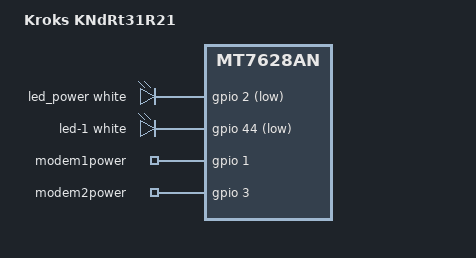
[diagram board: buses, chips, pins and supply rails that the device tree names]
#include "mt7628an_kroks_5eth.dtsi"

#include <dt-bindings/leds/common.h>

/ {
	compatible = "kroks,kndrt31r21", "mediatek,mt7628an-soc";
	model = "Kroks KNdRt31R21";

	aliases {
		led-boot = &led_power;
		led-failsafe = &led_power;
		led-running = &led_power;
		led-upgrade = &led_power;
	};

	gpio-leds {
		compatible = "gpio-leds";

		led_power: led-0 {
			color = <LED_COLOR_ID_WHITE>;
			gpios = <&gpio 2 GPIO_ACTIVE_LOW>;
			function = LED_FUNCTION_POWER;
		};

		led-1 {
			color = <LED_COLOR_ID_WHITE>;
			gpios = <&gpio 44 GPIO_ACTIVE_LOW>;
			function = LED_FUNCTION_WLAN;
			linux,default-trigger = "phy0tpt";
		};
	};

	gpio_export {
		compatible = "gpio-export";
		#size-cells = <0>;

		modem1power {
			gpio-export,name = "modem1power";
			gpio-export,output = <1>;
			gpios = <&gpio 1 GPIO_ACTIVE_HIGH>;
		};

		modem2power {
			gpio-export,name = "modem2power";
			gpio-export,output = <1>;
			gpios = <&gpio 3 GPIO_ACTIVE_HIGH>;
		};
	};
};

&state_default {
	gpio {
		groups = "i2s", "wled_an";
		function = "gpio";
	};
};
